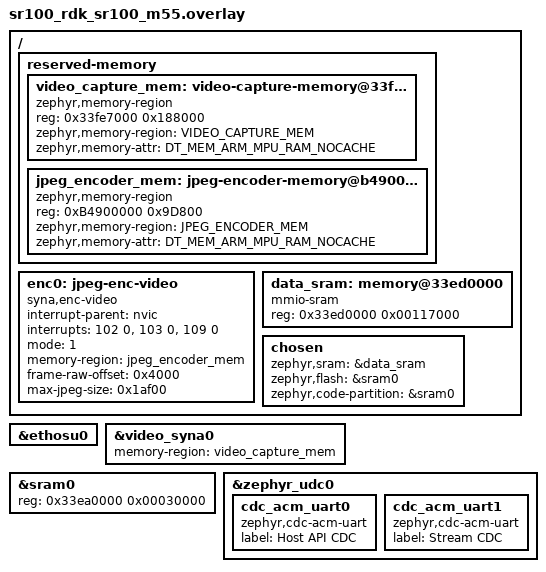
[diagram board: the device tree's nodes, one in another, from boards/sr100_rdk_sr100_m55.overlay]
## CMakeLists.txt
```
cmake_minimum_required(VERSION 3.20.0)
find_package(Zephyr REQUIRED HINTS $ENV{ZEPHYR_BASE})
project(person_detection_mipi)

set(NO_THREADSAFE_STATICS $<TARGET_PROPERTY:compiler-cpp,no_threadsafe_statics>)
zephyr_compile_options($<$<COMPILE_LANGUAGE:CXX>:${NO_THREADSAFE_STATICS}>)

target_sources(app PRIVATE
  src/main.c
  src/person_detection_mipi_capture.c
  src/person_detection_mipi_app.c
  src/person_detection_mipi_metadata.c
  src/person_detection_mipi_stream.c
  src/person_detection_mipi_inference.cpp
  src/person_detection_mipi_cmsis_shim.c
  src/infer_utils.c
  src/stream_cdc_transport.c
)
```

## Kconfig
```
# Copyright (c) 2026 Synaptics Incorporated
# SPDX-License-Identifier: Apache-2.0

mainmenu "Person Detection MIPI Sample"

config PERSON_DETECTION_MIPI_USECASE_ID
	int "UC manager usecase ID"
	default 2

config PERSON_DETECTION_MIPI_HOST_API_READY_TIMEOUT_MS
	int "Host API ready timeout (ms)"
	default 5000

config PERSON_DETECTION_MODEL_FLASH_ADDR
	hex "XIP flash address of the model binary"
	default 0x3C629000
	help
	  Start address in the XIP flash region where the TFLite model binary
	  has been programmed. Board-specific; adjust to match the flash
	  partition layout of the target hardware.

config PERSON_DETECTION_INPUT_FLASH_ADDR
	hex "XIP flash address of the input image binary"
	default 0x3CA00000
	help
	  Start address in the XIP flash region where the raw input image
	  binary has been programmed.

config PERSON_DETECTION_MODEL_SIZE
	int "Size of the model binary in bytes"
	default 1160832
	help
	  Byte length of the model binary stored at
	  PERSON_DETECTION_MODEL_FLASH_ADDR. Must match the actual file size
	  of the programmed model; a mismatch will silently copy wrong data.

source "Kconfig.zephyr"
```

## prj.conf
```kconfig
CONFIG_CPP=y
CONFIG_STD_CPP17=y
CONFIG_CONSOLE=y
CONFIG_PRINTK=y
CONFIG_STDOUT_CONSOLE=y
CONFIG_TENSORFLOW_LITE_MICRO=y
CONFIG_MAIN_STACK_SIZE=65536
CONFIG_SIZE_OPTIMIZATIONS=y
CONFIG_FPU=y
# Ethos-U55 NPU
CONFIG_ETHOS_U=y
CONFIG_ETHOS_U55_128=y
CONFIG_HEAP_MEM_POOL_SIZE=16384
CONFIG_LOG=n

CONFIG_VIDEO=y
CONFIG_VIDEO_INIT_PRIORITY=90
CONFIG_VIDEO_SYNA_MIPI=y
CONFIG_VIDEO_SYNA_ENC=y
CONFIG_VIDEO_SYNA_MIPI_INIT_PRIORITY=110
CONFIG_VIDEO_BUFFER_POOL_HEAP_SIZE=320000
CONFIG_VIDEO_BUFFER_POOL_NUM_MAX=4
CONFIG_VIDEO_BUFFER_POOL_ALIGN=64
CONFIG_POLL=y

CONFIG_GPIO=y
CONFIG_SERIAL=y
CONFIG_UART_INTERRUPT_DRIVEN=y
CONFIG_UART_LINE_CTRL=y
CONFIG_REBOOT=y

CONFIG_USB_DEVICE_STACK_NEXT=y
CONFIG_CDC_ACM_SERIAL_INITIALIZE_AT_BOOT=n
CONFIG_USBD_CDC_ACM_CLASS=y
CONFIG_USBD_MAX_SPEED_FULL=y
CONFIG_UDC_DRIVER_HIGH_SPEED_SUPPORT_ENABLED=n
CONFIG_USBD_BOS_SUPPORT=n
CONFIG_USBD_VREQ_SUPPORT=n
CONFIG_UDC_BUF_POOL_SIZE=2048
CONFIG_USBD_MAX_UDC_MSG=8
CONFIG_USBD_MSG_SLAB_COUNT=8
CONFIG_USBD_HWINFO_DEVID_LENGTH=8
CONFIG_USBD_THREAD_STACK_SIZE=2048
CONFIG_UDC_DWC2_STACK_SIZE=2048
CONFIG_USBD_LOG_LEVEL_ERR=y
CONFIG_UDC_DRIVER_LOG_LEVEL_ERR=y
CONFIG_USBD_CDC_ACM_LOG_LEVEL_ERR=y

CONFIG_SERVICE_HOST_API_ENABLED=y
CONFIG_SERVICE_USB_HOST_API_ENABLED=y
CONFIG_SERVICE_SYSTEM_ENABLED=y
CONFIG_SERVICE_UC_MANAGER_ENABLED=y
CONFIG_ACTIVE_INTERFACE_USB=y
CONFIG_HOST_API_AUTO_START=y
CONFIG_HOST_API_USB_VID=0xCAFE
CONFIG_HOST_API_USB_PID=0x4002
CONFIG_HOST_API_THREAD_STACK_SIZE=4096
CONFIG_HOST_API_TASK_PRIORITY=5
CONFIG_HOST_API_SDK_VER_MAJOR=0
CONFIG_HOST_API_SDK_VER_MINOR=9
CONFIG_HOST_API_SDK_VER_REVISION=7
```

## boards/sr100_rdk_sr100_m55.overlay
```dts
/*
 * Keep the Ethos-U activations in system RAM and reserve a non-cached
 * buffer pool for live MIPI capture.
 *
 * The board's default code partition is ITCM, which is too small for this
 * sample once TFLM, host API and live MIPI support are enabled. Move the
 * executable image to SRAM and keep runtime data in a separate SRAM window.
 */

#include <zephyr/dt-bindings/memory-attr/memory-attr-arm.h>

/ {
	reserved-memory {
		#address-cells = <1>;
		#size-cells = <1>;
		ranges;

		video_capture_mem: video-capture-memory@33fe7000 {
			compatible = "zephyr,memory-region", "mmio-sram";
			reg = <0x33fe7000 0x188000>;
			zephyr,memory-region = "VIDEO_CAPTURE_MEM";
			zephyr,memory-attr = <DT_MEM_ARM_MPU_RAM_NOCACHE>;
		};

		jpeg_encoder_mem: jpeg-encoder-memory@b4900000 {
			compatible = "zephyr,memory-region", "mmio-sram";
			reg = <0xB4900000 0x9D800>;
			zephyr,memory-region = "JPEG_ENCODER_MEM";
			zephyr,memory-attr = <DT_MEM_ARM_MPU_RAM_NOCACHE>;
		};
	};

	enc0: jpeg-enc-video {
		compatible = "syna,enc-video";
		status = "okay";
		interrupt-parent = <&nvic>;
		interrupts = <102 0>, <103 0>, <109 0>;
		interrupt-names = "frame-done", "fmin1-stored", "status";
		mode = <1>;
		memory-region = <&jpeg_encoder_mem>;
		frame-raw-offset = <0x4000>;
		max-jpeg-size = <0x1af00>;
	};
};

&ethosu0 {
	/delete-property/ fast-memory-region;
};

&video_syna0 {
	memory-region = <&video_capture_mem>;
};

&sram0 {
	/*
	 * Put code/rodata here so the application no longer depends on the
	 * 128 KB ITCM code partition. The current image uses about 149 KB of
	 * ROM, so 192 KB leaves margin while preserving the rest of SRAM for
	 * data sections.
	 */
	reg = <0x33ea0000 0x00030000>;
	ranges = <0x0 0x33ea0000 0x00030000>;
};

/ {
	data_sram: memory@33ed0000 {
		compatible = "mmio-sram";
		reg = <0x33ed0000 0x00117000>;
		#address-cells = <1>;
		#size-cells = <1>;
		ranges = <0x0 0x33ed0000 0x00117000>;
	};

	chosen {
		zephyr,sram = &data_sram;
		zephyr,flash = &sram0;
		zephyr,code-partition = &sram0;
	};
};

&zephyr_udc0 {
	cdc_acm_uart0: cdc_acm_uart0 {
		compatible = "zephyr,cdc-acm-uart";
		label = "Host API CDC";
	};

	cdc_acm_uart1: cdc_acm_uart1 {
		compatible = "zephyr,cdc-acm-uart";
		label = "Stream CDC";
	};
};
```

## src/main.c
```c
/*
 * Copyright (c) 2026 Synaptics Incorporated
 *
 * SPDX-License-Identifier: Apache-2.0
 */

/**
 * @file
 * @brief Host API controlled person detection MIPI sample shell
 */

#include <errno.h>
#include <stdint.h>

#include <zephyr/kernel.h>
#include <zephyr/sys/printk.h>

#include "person_detection_mipi_app.h"
#include "service_uc_manager_interface.h"

bool host_api_is_ready(void);

void host_api_loaded_apps_report(void)
{
	printk("zephyr_person_detection_mipi\n");
}

static int register_person_detection_usecase(void)
{
	static const uc_operations_t ops = {
		.create = person_detection_mipi_app_create,
		.start = person_detection_mipi_app_start,
		.stop = person_detection_mipi_app_stop,
		.resume = person_detection_mipi_app_resume,
		.kill = person_detection_mipi_app_kill,
	};

	return uc_manager_register_usecase((uint8_t)CONFIG_PERSON_DETECTION_MIPI_USECASE_ID,
					   &ops);
}

int main(void)
{
	int ret;

	printk("person_detection_mipi: main start\n");

	ret = register_person_detection_usecase();
	if (ret != 0) {
		printk("person_detection_mipi: usecase register failed: %d\n", ret);
		return ret;
	}

	printk("person_detection_mipi: usecase registered, waiting for host api\n");

	for (int elapsed = 0; elapsed < CONFIG_PERSON_DETECTION_MIPI_HOST_API_READY_TIMEOUT_MS;
	     elapsed += 10) {
		if (host_api_is_ready()) {
			printk("person_detection_mipi: host api ready\n");
			while (true) {
				k_sleep(K_FOREVER);
			}
		}

		k_msleep(10);
	}

	printk("person_detection_mipi: host api ready timeout\n");
	return -ETIMEDOUT;
}
```

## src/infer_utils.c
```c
/*
 * Copyright (c) 2026 Synaptics Incorporated
 *
 * SPDX-License-Identifier: Apache-2.0
 */

/**
 * @file
 * @brief Person-detection inference utilities: preprocess and postprocess implementation
 */

#include "infer_utils.h"
#include <stdint.h>
#include <math.h>

#ifdef __ARM_FEATURE_MVE
#include <arm_mve.h>
#endif

int infer_preprocess(void *addr, int width, int height)
{
    if (!addr || width <= 0 || height <= 0)
        return -1;

    size_t   total = (size_t)width * (size_t)height * 3u;
    uint8_t *p     = (uint8_t *)addr;

#ifdef __ARM_FEATURE_MVE
    const uint8x16_t mask = vdupq_n_u8(0x80u);
    int32_t          n    = (int32_t)total;
    do {
        mve_pred16_t pred = vctp8q((uint32_t)n);
        uint8x16_t   v    = vldrbq_z_u8(p, pred);
        vstrbq_p_u8(p, veorq_u8(v, mask), pred);
        p += 16;
        n -= 16;
    } while (n > 0);
#else
    if (((uintptr_t)addr & 3u) == 0u) {
        uint32_t      *p32  = (uint32_t *)addr;
        size_t         n32  = total >> 2;
        size_t         tail = total & 3u;
        const uint32_t M    = 0x80808080u;
        size_t i = 0;

        for (; i + 3 < n32; i += 4) {
            p32[i    ] ^= M;
            p32[i + 1] ^= M;
            p32[i + 2] ^= M;
            p32[i + 3] ^= M;
        }
        for (; i < n32; ++i) {
            p32[i] ^= M;
        }
        p = (uint8_t *)addr + (n32 << 2);
        for (size_t j = 0; j < tail; ++j) {
            p[j] ^= 0x80u;
        }
    } else {
        for (size_t i = 0; i < total; ++i) {
            p[i] ^= 0x80u;
        }
    }
#endif

    return 0;
}

/* Postprocessing constants */
static const float k_scale_x2y2   = 2.2298152446746826f;
static const int   k_zp_x2y2      = -84;
static const float k_scale_x1y1   = 2.4782917499542236f;
static const int   k_zp_x1y1      = -128;
static const float k_scale_scores = 0.00390625f; /* 1/256 */
static const int   k_zp_scores    = -128;

static float iou_xywh(const float *a, const float *b)
{
    float ax1 = a[0], ay1 = a[1], ax2 = a[0]+a[2], ay2 = a[1]+a[3];
    float bx1 = b[0], by1 = b[1], bx2 = b[0]+b[2], by2 = b[1]+b[3];
    float inter_w  = fmaxf(0.f, fminf(ax2,bx2) - fmaxf(ax1,bx1));
    float inter_h  = fmaxf(0.f, fminf(ay2,by2) - fmaxf(ay1,by1));
    float inter    = inter_w * inter_h;
    float uni      = a[2]*a[3] + b[2]*b[3] - inter;
    return (uni <= 0.f) ? 0.f : inter / uni;
}

static void min_heap_swap(int *h, int a, int b)
{
    int t = h[a]; h[a] = h[b]; h[b] = t;
}

static void min_heap_sift_up(int *h, int cnt, const float *scores, int cur)
{
    while (cur > 0 && cur < cnt) {
        int parent = (cur - 1) >> 1;
        if (scores[h[cur]] < scores[h[parent]]) {
            min_heap_swap(h, cur, parent);
            cur = parent;
        } else {
            break;
        }
    }
}

static void min_heap_sift_down(int *h, int cnt, const float *scores, int cur)
{
    for (;;) {
        int left = (cur << 1) + 1;
        int right = left + 1;
        int smallest = cur;
        if (left < cnt && scores[h[left]] < scores[h[smallest]]) smallest = left;
        if (right < cnt && scores[h[right]] < scores[h[smallest]]) smallest = right;
        if (smallest != cur) {
            min_heap_swap(h, cur, smallest);
            cur = smallest;
        } else break;
    }
}

int infer_postprocess(const void *box1_addr, size_t box1_size,
                      const void *cls_addr,  size_t cls_size,
                      const void *box2_addr, size_t box2_size,
                      int max_out, detection_t *out_dets, int *out_count)
{
    if (!box1_addr || !cls_addr || !box2_addr || !out_dets || !out_count)
        return -1;

    const int N = MAX_BOXES;
    if (box1_size < (size_t)N*2 || box2_size < (size_t)N*2 || cls_size < (size_t)N)
        return -2;

    const int8_t *box1 = (const int8_t *)box1_addr;
    const int8_t *box2 = (const int8_t *)box2_addr;
    const int8_t *cls  = (const int8_t *)cls_addr;

    /* Static temporaries to avoid heap usage */
    static float x1[MAX_BOXES];
    static float y1[MAX_BOXES];
    static float x2[MAX_BOXES];
    static float y2[MAX_BOXES];
    static float scores[MAX_BOXES];
    static float boxes[MAX_BOXES * 4u];
    static uint8_t valid[MAX_BOXES];

    /* Scalar decode (portable) */
    for (int i = 0; i < N; ++i) {
        x2[i]     = (float)((int)box1[i*2+0] - k_zp_x2y2)  * k_scale_x2y2;
        y2[i]     = (float)((int)box1[i*2+1] - k_zp_x2y2)  * k_scale_x2y2;
        x1[i]     = (float)((int)box2[i*2+0] - k_zp_x1y1)  * k_scale_x1y1;
        y1[i]     = (float)((int)box2[i*2+1] - k_zp_x1y1)  * k_scale_x1y1;
        scores[i] = (float)((int)cls[i]       - k_zp_scores) * k_scale_scores;
    }

    for (int i = 0; i < N; ++i) {
        float xmin = fminf(x1[i], x2[i]);
        float xmax = fmaxf(x1[i], x2[i]);
        float ymin = fminf(y1[i], y2[i]);
        float ymax = fmaxf(y1[i], y2[i]);
        float bw   = xmax - xmin;
        float bh   = ymax - ymin;
        if (bw > 1.f && bh > 1.f) {
            boxes[4*i+0] = xmin;
            boxes[4*i+1] = ymin;
            boxes[4*i+2] = bw;
            boxes[4*i+3] = bh;
            valid[i] = 1u;
        } else {
            valid[i] = 0u;
        }
    }

    const float conf_thresh = 0.25f;
    const float iou_thresh  = 0.6f;

    const int nms_cap = (max_out < NMS_MAX_KEEP) ? max_out : NMS_MAX_KEEP;
    if (nms_cap <= 0) {
        *out_count = 0;
        return 0;
    }

    /* Bounded min-heap (by score) of candidate indices */
    int heap_cnt = 0;
    int heap_idx[NMS_MAX_KEEP];

    /* heap operations use static helpers defined above */

    for (int i = 0; i < N; ++i) {
        if (!valid[i]) continue;
        float s = scores[i];
        if (s <= conf_thresh) continue;
        if (heap_cnt < nms_cap) {
            heap_idx[heap_cnt] = i;
            min_heap_sift_up(heap_idx, heap_cnt + 1, scores, heap_cnt);
            heap_cnt++;
        } else if (s > scores[heap_idx[0]]) {
            heap_idx[0] = i;
            min_heap_sift_down(heap_idx, heap_cnt, scores, 0);
        }
    }

    if (heap_cnt == 0) {
        *out_count = 0;
        return 0;
    }

    /* Extract heap into candidates array in descending order */
    int candidates_count = heap_cnt;
    int candidates_arr[NMS_MAX_KEEP];
    for (int i = heap_cnt - 1; i >= 0; --i) {
        candidates_arr[i] = heap_idx[0];
        heap_idx[0] = heap_idx[heap_cnt - 1];
        heap_cnt--;
        if (heap_cnt > 0) min_heap_sift_down(heap_idx, heap_cnt, scores, 0);
    }

    /* Perform NMS on the top candidates */
    int num_kept = 0;
    int kept[NMS_MAX_KEEP];
    for (int i = 0; i < candidates_count && num_kept < nms_cap; ++i) {
        int idx = candidates_arr[i];
        float bi[4] = { boxes[4*idx], boxes[4*idx+1], boxes[4*idx+2], boxes[4*idx+3] };
        int suppress = 0;
        for (int j = 0; j < num_kept && !suppress; ++j) {
            int ki = kept[j];
            float bj[4] = { boxes[4*ki], boxes[4*ki+1], boxes[4*ki+2], boxes[4*ki+3] };
            if (iou_xywh(bi, bj) > iou_thresh)
                suppress = 1;
        }
        if (!suppress)
            kept[num_kept++] = idx;
    }

    /* Fill output detections */
    for (int i = 0; i < num_kept; ++i) {
        int idx = kept[i];
        out_dets[i].class_id = 0;
        out_dets[i].score    = scores[idx];
        out_dets[i].x        = boxes[4*idx+0];
        out_dets[i].y        = boxes[4*idx+1];
        out_dets[i].w        = boxes[4*idx+2];
        out_dets[i].h        = boxes[4*idx+3];
    }

    *out_count = num_kept;
    return 0;
}
```

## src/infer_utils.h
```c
/*
 * Copyright (c) 2026 Synaptics Incorporated
 *
 * SPDX-License-Identifier: Apache-2.0
 */

/**
 * @file
 * @brief Person-detection inference utilities: preprocess and postprocess API
 */

#ifndef INFER_UTILS_H_
#define INFER_UTILS_H_

#include <stddef.h>

/**
 * @brief Maximum number of detections the postprocessor will return
 */
#define MAX_DETECTIONS   16

/**
 * @brief Maximum number of candidate boxes produced by the network
 */
#define MAX_BOXES        600

/**
 * @brief Maximum number of boxes to keep during non-max suppression
 */
#define NMS_MAX_KEEP     6

/**
 * @struct detection_t
 * @brief Single detection result in pixel coordinates
 *
 * - `class_id` currently always 0 for the person model
 * - `score` is the confidence (0.0 - 1.0)
 * - `x, y` are the top-left pixel coordinates
 * - `w, h` are the width and height in pixels
 */
typedef struct {
    int   class_id;
    float score;
    float x;
    float y;
    float w;
    float h;
} detection_t;

#ifdef __cplusplus
extern "C" {
#endif

/**
 * @brief Preprocess an input image in-place for the model.
 *
 * The sample stores inputs in flash as interleaved RGB uint8. The model
 * expects int8 with a zero-point conversion performed by XOR 0x80. This
 * function applies that conversion in-place.
 *
 * @param addr Pointer to image buffer (must be writable). The buffer layout
 *             is interleaved RGB, row-major, size = width * height * 3 bytes.
 * @param width Image width in pixels.
 * @param height Image height in pixels.
 * @return 0 on success, negative on error (invalid args).
 */
int infer_preprocess(void *addr, int width, int height);

/**
 * @brief Postprocess raw network outputs into detection_t array.
 *
 * The function decodes the model's three output tensors into bounding boxes
 * and scores, applies non-max suppression, and fills the provided output
 * array with up to `max_out` detections.
 *
 * @param box1_addr Pointer to first box tensor data (raw int8/uint8 as produced by the model)
 * @param box1_size Size in bytes of the first box tensor.
 * @param cls_addr  Pointer to class/score tensor data.
 * @param cls_size  Size in bytes of the class/score tensor.
 * @param box2_addr Pointer to second box tensor data (if applicable).
 * @param box2_size Size in bytes of the second box tensor.
 * @param max_out Maximum number of detections to write into `out_dets`.
 * @param out_dets Pointer to caller-allocated array of `detection_t` of length >= max_out.
 * @param out_count Pointer to int updated with the number of detections written.
 * @return 0 on success, negative on error.
 */
int infer_postprocess(const void *box1_addr, size_t box1_size,
                      const void *cls_addr,  size_t cls_size,
                      const void *box2_addr, size_t box2_size,
                      int max_out, detection_t *out_dets, int *out_count);

#ifdef __cplusplus
}
#endif

#endif /* INFER_UTILS_H_ */
```

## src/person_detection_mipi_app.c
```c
/*
 * Copyright (c) 2026 Synaptics Incorporated
 *
 * SPDX-License-Identifier: Apache-2.0
 */

#include "person_detection_mipi_app.h"

#include <errno.h>
#include <stdbool.h>

#include "person_detection_mipi_capture.h"
#include "person_detection_mipi_inference.h"
#include "person_detection_mipi_metadata.h"
#include "person_detection_mipi_stream.h"

#include <zephyr/kernel.h>
#include <zephyr/sys/printk.h>

enum person_detection_mipi_state {
	APP_STATE_UNINITIALIZED = 0,
	APP_STATE_CREATED,
	APP_STATE_RUNNING,
	APP_STATE_STOPPED,
};

struct person_detection_mipi_context {
	struct k_mutex lock;
	struct k_sem inference_ready_sem;
	struct k_sem inference_stopped_sem;
	struct k_thread inference_thread;
	enum person_detection_mipi_state state;
	bool stop_requested;
	bool inference_running;
	bool initialized;
};

static struct person_detection_mipi_context app_ctx;

K_THREAD_STACK_DEFINE(person_detection_mipi_inference_stack, 4096);

static void app_context_init(struct person_detection_mipi_context *ctx)
{
	if (ctx->initialized) {
		return;
	}

	k_mutex_init(&ctx->lock);
	k_sem_init(&ctx->inference_ready_sem, 0, 1);
	k_sem_init(&ctx->inference_stopped_sem, 0, 1);
	ctx->state = APP_STATE_UNINITIALIZED;
	ctx->initialized = true;
}

static void person_detection_mipi_inference_worker(void *arg1, void *arg2, void *arg3)
{
	struct person_detection_mipi_context *ctx = arg1;
	struct person_detection_mipi_capture_frame frame;
	struct person_detection_mipi_inference_result result;
	uint8_t *scratch_frame = person_detection_mipi_capture_scratch_frame_buffer();
	uint32_t last_sequence = 0U;
	uint32_t loops_without_frame = 0U;
	uint32_t loops_without_new_frame = 0U;
	uint32_t inference_count = 0U;
	bool ready_signaled = false;

	ARG_UNUSED(arg2);
	ARG_UNUSED(arg3);

	printk("person_detection_mipi: inference worker: started\n");

	while (true) {
		bool stop_requested;
		int ret;

		k_mutex_lock(&ctx->lock, K_FOREVER);
		stop_requested = ctx->stop_requested;
		k_mutex_unlock(&ctx->lock);

		if (stop_requested) {
			break;
		}

		ret = person_detection_mipi_capture_get_latest(&frame, scratch_frame,
							       PERSON_DETECTION_MIPI_MODEL_RAW_FRAME_SIZE);
		if (ret != 0) {
			loops_without_frame++;
			if ((loops_without_frame == 1U) || ((loops_without_frame % 100U) == 0U)) {
				printk("person_detection_mipi: inference worker: no frame yet (ret=%d loops=%u)\n",
				       ret, loops_without_frame);
			}
			k_msleep(10);
			continue;
		}
		loops_without_frame = 0U;

		if ((frame.sequence == 0U) || (frame.sequence == last_sequence) || !frame.valid) {
			loops_without_new_frame++;
			if ((loops_without_new_frame == 1U) ||
			    ((loops_without_new_frame % 100U) == 0U)) {
				printk("person_detection_mipi: inference worker: waiting for new frame (seq=%u last=%u valid=%d loops=%u)\n",
				       frame.sequence, last_sequence, frame.valid ? 1 : 0,
				       loops_without_new_frame);
			}
			k_msleep(10);
			continue;
		}
		loops_without_new_frame = 0U;

		printk("person_detection_mipi: inference worker: running frame seq=%u bytes=%u\n",
		       frame.sequence, frame.bytesused);

		ret = person_detection_mipi_inference_run_raw8_frame(frame.data, frame.bytesused,
								     &result);
		if (ret != 0) {
			printk("person_detection_mipi: inference worker: inference failed for seq=%u ret=%d\n",
			       frame.sequence, ret);
			continue;
		}

		inference_count++;
		printk("person_detection_mipi: inference worker: frame seq=%u done invoke=%ums detections=%d total=%u\n",
		       frame.sequence, result.invoke_time_ms, result.detection_count, inference_count);
		if (result.detection_count > 0) {
			for (int i = 0; i < result.detection_count; i++) {
				const detection_t *det = &result.detections[i];
				float x1 = det->x;
				float y1 = det->y;
				float x2 = det->x + det->w;
				float y2 = det->y + det->h;

				printk("UC Person detection - [Frame %u] Detection number %d: Class [%d], Box [%0.3f, %0.3f, %0.3f, %0.3f], Score [%0.3f]\n",
				       frame.sequence, i + 1, det->class_id,
				       (double)x1, (double)y1, (double)x2, (double)y2,
				       (double)det->score);
			}
		}

		ret = person_detection_mipi_metadata_update(frame.sequence,
							   CONFIG_PERSON_DETECTION_MIPI_USECASE_ID,
							   &result);
		if (ret != 0) {
			printk("person_detection_mipi: inference worker: metadata update failed for seq=%u ret=%d\n",
			       frame.sequence, ret);
			continue;
		}
		printk("person_detection_mipi: inference worker: metadata updated for seq=%u\n",
		       frame.sequence);

		last_sequence = frame.sequence;

		if (!ready_signaled) {
			ready_signaled = true;
			k_sem_give(&ctx->inference_ready_sem);
		}
	}

	k_mutex_lock(&ctx->lock, K_FOREVER);
	ctx->inference_running = false;
	k_mutex_unlock(&ctx->lock);

	printk("person_detection_mipi: inference worker: stopped after %u successful inference(s)\n",
	       inference_count);

	if (!ready_signaled) {
		k_sem_give(&ctx->inference_ready_sem);
	}

	k_sem_give(&ctx->inference_stopped_sem);
}

int person_detection_mipi_app_create(void)
{
	struct person_detection_mipi_context *ctx = &app_ctx;
	int ret;

	app_context_init(ctx);
	k_mutex_lock(&ctx->lock, K_FOREVER);

	if (ctx->state != APP_STATE_UNINITIALIZED) {
		k_mutex_unlock(&ctx->lock);
		return 0;
	}

	printk("person_detection_mipi: create: initializing inference\n");
	ret = person_detection_mipi_inference_init();
	if (ret != 0) {
		printk("person_detection_mipi: create: inference init failed: %d\n", ret);
		k_mutex_unlock(&ctx->lock);
		return ret;
	}

	printk("person_detection_mipi: create: initializing MIPI capture\n");
	ret = person_detection_mipi_capture_init();
	if (ret != 0) {
		printk("person_detection_mipi: create: MIPI capture init failed: %d\n", ret);
		k_mutex_unlock(&ctx->lock);
		return ret;
	}

	printk("person_detection_mipi: create: initializing JPEG stream\n");
	ret = person_detection_mipi_stream_init();
	if (ret != 0) {
		printk("person_detection_mipi: create: JPEG stream disabled: %d\n", ret);
	}

	person_detection_mipi_metadata_reset();

	ctx->state = APP_STATE_CREATED;

	k_mutex_unlock(&ctx->lock);
	printk("person_detection_mipi: create: complete\n");
	return 0;
}

int person_detection_mipi_app_start(void)
{
	struct person_detection_mipi_context *ctx = &app_ctx;
	int ret = 0;

	app_context_init(ctx);
	k_mutex_lock(&ctx->lock, K_FOREVER);

	if (ctx->state == APP_STATE_RUNNING) {
		k_mutex_unlock(&ctx->lock);
		return 0;
	}

	if (ctx->state == APP_STATE_STOPPED) {
		k_mutex_unlock(&ctx->lock);
		return person_detection_mipi_app_resume();
	}

	if (ctx->state != APP_STATE_CREATED) {
		k_mutex_unlock(&ctx->lock);
		return -EPERM;
	}

	k_mutex_unlock(&ctx->lock);

	ret = person_detection_mipi_stream_start();
	if (ret != 0) {
		printk("person_detection_mipi: start: JPEG stream disabled: %d\n", ret);
	}

	printk("person_detection_mipi: start: starting MIPI capture\n");
	ret = person_detection_mipi_capture_start();
	if (ret != 0) {
		(void)person_detection_mipi_stream_stop();
		printk("person_detection_mipi: start: MIPI capture failed: %d\n", ret);
		return ret;
	}

	person_detection_mipi_metadata_reset();

	k_mutex_lock(&ctx->lock, K_FOREVER);
	ctx->stop_requested = false;
	ctx->inference_running = true;
	k_sem_reset(&ctx->inference_ready_sem);
	k_sem_reset(&ctx->inference_stopped_sem);
	k_mutex_unlock(&ctx->lock);

	k_thread_create(&ctx->inference_thread, person_detection_mipi_inference_stack,
			K_THREAD_STACK_SIZEOF(person_detection_mipi_inference_stack),
			person_detection_mipi_inference_worker, ctx, NULL, NULL,
			CONFIG_HOST_API_TASK_PRIORITY, 0, K_NO_WAIT);
	k_thread_name_set(&ctx->inference_thread, "pd_mipi_infer");

	printk("person_detection_mipi: start: waiting for first inference\n");
	ret = k_sem_take(&ctx->inference_ready_sem, K_SECONDS(5));
	if (ret != 0) {
		printk("person_detection_mipi: start: first inference timeout: %d\n", ret);
		k_mutex_lock(&ctx->lock, K_FOREVER);
		ctx->stop_requested = true;
		k_mutex_unlock(&ctx->lock);
		(void)person_detection_mipi_stream_stop();
		(void)person_detection_mipi_capture_stop();
		(void)k_sem_take(&ctx->inference_stopped_sem, K_SECONDS(5));
		return ret;
	}

	k_mutex_lock(&ctx->lock, K_FOREVER);
	ctx->state = APP_STATE_RUNNING;
	k_mutex_unlock(&ctx->lock);
	printk("person_detection_mipi: start: complete\n");
	return 0;
}

int person_detection_mipi_app_stop(void)
{
	struct person_detection_mipi_context *ctx = &app_ctx;
	int ret = 0;

	app_context_init(ctx);
	k_mutex_lock(&ctx->lock, K_FOREVER);

	if (ctx->state == APP_STATE_STOPPED) {
		k_mutex_unlock(&ctx->lock);
		return 0;
	}

	if (ctx->state != APP_STATE_RUNNING) {
		k_mutex_unlock(&ctx->lock);
		return -EPERM;
	}

	ctx->stop_requested = true;
	k_mutex_unlock(&ctx->lock);

	ret = person_detection_mipi_stream_pause();
	if (ret != 0) {
		printk("person_detection_mipi: stop: JPEG stream pause failed: %d\n", ret);
		return ret;
	}

	ret = k_sem_take(&ctx->inference_stopped_sem, K_SECONDS(5));
	if (ret != 0) {
		return ret;
	}

	k_mutex_lock(&ctx->lock, K_FOREVER);
	ctx->state = APP_STATE_STOPPED;
	k_mutex_unlock(&ctx->lock);
	printk("person_detection_mipi: stop: complete\n");
	return 0;
}

int person_detection_mipi_app_resume(void)
{
	struct person_detection_mipi_context *ctx = &app_ctx;
	int ret;

	app_context_init(ctx);
	k_mutex_lock(&ctx->lock, K_FOREVER);
	if (ctx->state != APP_STATE_STOPPED) {
		k_mutex_unlock(&ctx->lock);
		return -EPERM;
	}
	k_mutex_unlock(&ctx->lock);

	printk("person_detection_mipi: resume: resuming paused usecase\n");

	ret = person_detection_mipi_stream_resume();
	if (ret != 0) {
		printk("person_detection_mipi: resume: JPEG stream resume failed: %d\n", ret);
		return ret;
	}

	k_mutex_lock(&ctx->lock, K_FOREVER);
	ctx->stop_requested = false;
	ctx->inference_running = true;
	k_sem_reset(&ctx->inference_ready_sem);
	k_sem_reset(&ctx->inference_stopped_sem);
	k_mutex_unlock(&ctx->lock);

	k_thread_create(&ctx->inference_thread, person_detection_mipi_inference_stack,
			K_THREAD_STACK_SIZEOF(person_detection_mipi_inference_stack),
			person_detection_mipi_inference_worker, ctx, NULL, NULL,
			CONFIG_HOST_API_TASK_PRIORITY, 0, K_NO_WAIT);
	k_thread_name_set(&ctx->inference_thread, "pd_mipi_infer");

	printk("person_detection_mipi: resume: waiting for first inference\n");
	ret = k_sem_take(&ctx->inference_ready_sem, K_SECONDS(5));
	if (ret != 0) {
		printk("person_detection_mipi: resume: first inference timeout: %d\n", ret);
		k_mutex_lock(&ctx->lock, K_FOREVER);
		ctx->stop_requested = true;
		k_mutex_unlock(&ctx->lock);
		(void)person_detection_mipi_stream_pause();
		(void)k_sem_take(&ctx->inference_stopped_sem, K_SECONDS(5));
		return ret;
	}

	k_mutex_lock(&ctx->lock, K_FOREVER);
	ctx->state = APP_STATE_RUNNING;
	k_mutex_unlock(&ctx->lock);

	printk("person_detection_mipi: resume: complete\n");
	return 0;
}

int person_detection_mipi_app_kill(void)
{
	struct person_detection_mipi_context *ctx = &app_ctx;
	enum person_detection_mipi_state state;
	int ret;

	app_context_init(ctx);
	k_mutex_lock(&ctx->lock, K_FOREVER);
	state = ctx->state;
	k_mutex_unlock(&ctx->lock);

	if (state == APP_STATE_RUNNING) {
		ret = person_detection_mipi_app_stop();
		if (ret != 0) {
			printk("person_detection_mipi: kill: stop failed: %d\n", ret);
			return ret;
		}
		state = APP_STATE_STOPPED;
	}

	if (state == APP_STATE_STOPPED) {
		ret = person_detection_mipi_stream_stop();
		if (ret != 0) {
			printk("person_detection_mipi: kill: stream stop failed: %d\n", ret);
			return ret;
		}

		ret = person_detection_mipi_capture_stop();
		if (ret != 0) {
			printk("person_detection_mipi: kill: capture stop failed: %d\n", ret);
			return ret;
		}
	}

	person_detection_mipi_metadata_reset();

	k_mutex_lock(&ctx->lock, K_FOREVER);
	ctx->stop_requested = false;
	ctx->inference_running = false;
	ctx->state = APP_STATE_UNINITIALIZED;
	k_mutex_unlock(&ctx->lock);

	printk("person_detection_mipi: kill: complete\n");
	return 0;
}

int person_detection_mipi_app_get_latest_metadata(char *dst, size_t dst_size)
{
	return person_detection_mipi_metadata_get(dst, dst_size);
}

int person_detection_mipi_app_get_latest_snapshot(
	struct person_detection_mipi_metadata_snapshot *snapshot)
{
	return person_detection_mipi_metadata_snapshot_get(snapshot);
}

bool person_detection_mipi_app_is_running(void)
{
	struct person_detection_mipi_context *ctx = &app_ctx;
	bool running;

	app_context_init(ctx);
	k_mutex_lock(&ctx->lock, K_FOREVER);
	running = (ctx->state == APP_STATE_RUNNING);
	k_mutex_unlock(&ctx->lock);

	return running;
}
```

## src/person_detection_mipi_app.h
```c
/*
 * Copyright (c) 2026 Synaptics Incorporated
 *
 * SPDX-License-Identifier: Apache-2.0
 */

#ifndef PERSON_DETECTION_MIPI_APP_H_
#define PERSON_DETECTION_MIPI_APP_H_

#include <stddef.h>
#include <stdbool.h>

#include "person_detection_mipi_metadata.h"

#ifdef __cplusplus
extern "C" {
#endif

int person_detection_mipi_app_create(void);
int person_detection_mipi_app_start(void);
int person_detection_mipi_app_stop(void);
int person_detection_mipi_app_resume(void);
int person_detection_mipi_app_kill(void);
int person_detection_mipi_app_get_latest_metadata(char *dst, size_t dst_size);
int person_detection_mipi_app_get_latest_snapshot(
	struct person_detection_mipi_metadata_snapshot *snapshot);
bool person_detection_mipi_app_is_running(void);

#ifdef __cplusplus
}
#endif

#endif /* PERSON_DETECTION_MIPI_APP_H_ */
```

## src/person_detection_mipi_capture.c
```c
/*
 * Copyright (c) 2026 Synaptics Incorporated
 *
 * SPDX-License-Identifier: Apache-2.0
 */

#include "person_detection_mipi_capture.h"

#include <errno.h>
#include <string.h>

#include <zephyr/device.h>
#include <zephyr/devicetree.h>
#include <zephyr/drivers/video.h>
#include <zephyr/kernel.h>
#include <zephyr/sys/printk.h>
#include <zephyr/sys/util.h>

#include "person_detection_mipi_stream.h"

#define MIPI_DEV_NODE DT_NODELABEL(video_syna0)

#if !DT_NODE_EXISTS(MIPI_DEV_NODE)
#error "Devicetree node 'video_syna0' is required for this sample"
#endif

#if !DT_NODE_HAS_PROP(MIPI_DEV_NODE, memory_region)
#error "video_syna0 must provide a memory-region for live MIPI capture"
#endif

#define CAPTURE_MEM_NODE DT_PHANDLE(MIPI_DEV_NODE, memory_region)
#define CAPTURE_MEM_BASE DT_REG_ADDR(CAPTURE_MEM_NODE)
#define CAPTURE_MEM_SIZE DT_REG_SIZE(CAPTURE_MEM_NODE)

#define APP_CAPTURE_TIMEOUT K_SECONDS(5)
#define APP_CAPTURE_FIRST_FRAME_TIMEOUT K_SECONDS(5)
#define APP_CAPTURE_FRMIVAL_NUMERATOR 1U
#define APP_CAPTURE_FRMIVAL_DENOMINATOR 3U
#define APP_CAPTURE_BUFFER_COUNT 2U

/* The MIPI driver always DMA-writes one raw frame at the pool base. */
#define APP_CAPTURE_DMA_STAGING_OFFSET 0U
#define APP_CAPTURE_FULL_LATEST_FRAME_OFFSET \
	(APP_CAPTURE_DMA_STAGING_OFFSET + PERSON_DETECTION_MIPI_CAPTURE_FRAME_SIZE)
#define APP_CAPTURE_LATEST_FRAME_OFFSET \
	(APP_CAPTURE_FULL_LATEST_FRAME_OFFSET + PERSON_DETECTION_MIPI_CAPTURE_FRAME_SIZE)
#define APP_CAPTURE_SCRATCH_FRAME_OFFSET \
	(APP_CAPTURE_LATEST_FRAME_OFFSET + PERSON_DETECTION_MIPI_MODEL_RAW_FRAME_SIZE)
#define APP_CAPTURE_INPUT_BUF_OFFSET \
	(APP_CAPTURE_SCRATCH_FRAME_OFFSET + PERSON_DETECTION_MIPI_MODEL_RAW_FRAME_SIZE)
#define APP_CAPTURE_RESERVED_TOTAL_SIZE APP_CAPTURE_INPUT_BUF_OFFSET

BUILD_ASSERT(CAPTURE_MEM_SIZE >= APP_CAPTURE_RESERVED_TOTAL_SIZE,
	     "Capture reserved memory is too small for frame buffers");

static uint8_t *const app_capture_mem = (uint8_t *)CAPTURE_MEM_BASE;

enum capture_state {
	CAPTURE_STATE_UNINITIALIZED = 0,
	CAPTURE_STATE_READY,
	CAPTURE_STATE_RUNNING,
	CAPTURE_STATE_STOPPED,
};

struct capture_context {
	struct k_mutex lock;
	struct k_sem first_frame_sem;
	struct k_sem worker_stopped_sem;
	struct k_thread worker_thread;
	const struct device *mipi_dev;
	struct video_caps caps;
	struct video_format fmt;
	struct video_frmival frmival;
	struct video_buffer *vbufs[APP_CAPTURE_BUFFER_COUNT];
	enum capture_state state;
	bool initialized;
	bool stop_requested;
	bool stream_started;
	bool buffers_queued;
	bool latest_valid;
	int worker_result;
	uint32_t latest_bytesused;
	uint32_t latest_timestamp;
	uint32_t latest_sequence;
	uint32_t frames_captured;
};

static struct capture_context app_ctx;

K_THREAD_STACK_DEFINE(capture_worker_stack, 4096);

static void capture_context_init(struct capture_context *ctx)
{
	if (ctx->initialized) {
		return;
	}

	k_mutex_init(&ctx->lock);
	k_sem_init(&ctx->first_frame_sem, 0, 1);
	k_sem_init(&ctx->worker_stopped_sem, 0, 1);
	ctx->initialized = true;
}

static void drain_buffers(const struct device *dev)
{
	struct video_buffer *vbuf = NULL;
	uint32_t drained = 0U;

	while ((video_dequeue(dev, &vbuf, K_NO_WAIT) == 0) && (vbuf != NULL)) {
		drained++;
		vbuf->bytesused = 0U;
	}

	if (drained > 0U) {
		printk("person_detection_mipi: drained %u returned capture buffer(s)\n", drained);
	}
}

static int prepare_device_locked(struct capture_context *ctx)
{
	ctx->mipi_dev = DEVICE_DT_GET(MIPI_DEV_NODE);

	if (!device_is_ready(ctx->mipi_dev)) {
		return -ENODEV;
	}

	memset(&ctx->caps, 0, sizeof(ctx->caps));
	ctx->caps.type = VIDEO_BUF_TYPE_OUTPUT;

	return video_get_caps(ctx->mipi_dev, &ctx->caps);
}

static int configure_mipi_locked(struct capture_context *ctx)
{
	int ret;

	ctx->fmt = (struct video_format) {
		.type = VIDEO_BUF_TYPE_OUTPUT,
		.pixelformat = VIDEO_PIX_FMT_SRGGB8,
		.width = PERSON_DETECTION_MIPI_CAPTURE_WIDTH,
		.height = PERSON_DETECTION_MIPI_CAPTURE_HEIGHT,
		.pitch = PERSON_DETECTION_MIPI_CAPTURE_PITCH,
	};

	ret = video_set_format(ctx->mipi_dev, &ctx->fmt);
	if (ret != 0) {
		return ret;
	}

	printk("person_detection_mipi: negotiated fmt width=%u height=%u pitch=%u size=%u\n",
	       ctx->fmt.width, ctx->fmt.height, ctx->fmt.pitch, ctx->fmt.size);

	ctx->frmival = (struct video_frmival) {
		.numerator = APP_CAPTURE_FRMIVAL_NUMERATOR,
		.denominator = APP_CAPTURE_FRMIVAL_DENOMINATOR,
	};

	ret = video_set_frmival(ctx->mipi_dev, &ctx->frmival);
	if (ret != 0) {
		return ret;
	}

	return 0;
}

static int prepare_capture_buffers(struct capture_context *ctx)
{
	const size_t align = MAX(ctx->caps.buf_align, 1U);

	if (ctx->caps.min_vbuf_count > APP_CAPTURE_BUFFER_COUNT) {
		return -ENOMEM;
	}

	for (uint32_t i = 0U; i < APP_CAPTURE_BUFFER_COUNT; i++) {
		if (ctx->vbufs[i] == NULL) {
			ctx->vbufs[i] = video_buffer_aligned_alloc(ctx->fmt.size, align,
								   K_NO_WAIT);
			if (ctx->vbufs[i] == NULL) {
				printk("person_detection_mipi: capture buffer[%u] alloc failed\n",
				       i);
				return -ENOMEM;
			}
		}

		ctx->vbufs[i]->driver_data = NULL;
		ctx->vbufs[i]->type = VIDEO_BUF_TYPE_OUTPUT;
		ctx->vbufs[i]->bytesused = 0U;
		ctx->vbufs[i]->timestamp = 0U;
		printk("person_detection_mipi: capture buffer[%u] addr=%p size=%u\n", i,
		       ctx->vbufs[i]->buffer, ctx->vbufs[i]->size);
	}

	return 0;
}

static int queue_capture_buffers(struct capture_context *ctx)
{
	for (uint32_t i = 0U; i < APP_CAPTURE_BUFFER_COUNT; i++) {
		printk("person_detection_mipi: queue buffer[%u]\n", i);
		int ret = video_enqueue(ctx->mipi_dev, ctx->vbufs[i]);

		if (ret != 0) {
			printk("person_detection_mipi: queue buffer[%u] failed: %d\n", i, ret);
			return ret;
		}

		ctx->buffers_queued = true;
	}

	return 0;
}

static int copy_latest_frame_locked(struct capture_context *ctx, const struct video_buffer *src)
{
	if ((src == NULL) || (src->buffer == NULL)) {
		return -EINVAL;
	}

	if (src->bytesused < PERSON_DETECTION_MIPI_CAPTURE_FRAME_SIZE) {
		return -EINVAL;
	}

	memcpy(app_capture_mem + APP_CAPTURE_FULL_LATEST_FRAME_OFFSET,
	       src->buffer, PERSON_DETECTION_MIPI_CAPTURE_FRAME_SIZE);

	/* Match the parent usecase: crop the top-left 480x256 model window in place. */
	for (size_t row = 0U; row < 256U; row++) {
		memcpy(app_capture_mem + APP_CAPTURE_LATEST_FRAME_OFFSET +
		       (row * PERSON_DETECTION_MIPI_CAPTURE_WIDTH),
		       (const uint8_t *)src->buffer + (row * PERSON_DETECTION_MIPI_CAPTURE_PITCH),
		       PERSON_DETECTION_MIPI_CAPTURE_WIDTH);
	}
	ctx->latest_valid = true;
	ctx->latest_bytesused = PERSON_DETECTION_MIPI_MODEL_RAW_FRAME_SIZE;
	ctx->latest_timestamp = src->timestamp;
	ctx->latest_sequence++;
	ctx->frames_captured++;

	return 0;
}

static void capture_worker(void *arg1, void *arg2, void *arg3)
{
	struct capture_context *ctx = arg1;
	struct video_buffer *captured = NULL;
	bool started = false;
	int ret;

	ARG_UNUSED(arg2);
	ARG_UNUSED(arg3);

	ret = prepare_capture_buffers(ctx);
	if (ret != 0) {
		printk("person_detection_mipi: capture worker: prepare buffers failed: %d\n", ret);
		goto out;
	}

	ret = queue_capture_buffers(ctx);
	if (ret != 0) {
		printk("person_detection_mipi: capture worker: queue buffers failed: %d\n", ret);
		goto out;
	}

	ret = video_stream_start(ctx->mipi_dev, VIDEO_BUF_TYPE_OUTPUT);
	if (ret != 0) {
		printk("person_detection_mipi: capture worker: stream start failed: %d\n", ret);
		goto out;
	}
	started = true;

	while (!ctx->stop_requested) {
		ret = video_dequeue(ctx->mipi_dev, &captured, APP_CAPTURE_TIMEOUT);
		if (ret != 0) {
			if (ctx->stop_requested) {
				break;
			}
			printk("person_detection_mipi: capture worker: dequeue failed: %d\n", ret);
			goto out;
		}

		if (captured == NULL) {
			ret = -EIO;
			printk("person_detection_mipi: capture worker: dequeue returned NULL buffer\n");
			goto out;
		}

		k_mutex_lock(&ctx->lock, K_FOREVER);
		ret = copy_latest_frame_locked(ctx, captured);
		k_mutex_unlock(&ctx->lock);
		if (ret != 0) {
			printk("person_detection_mipi: capture worker: copy latest failed: %d\n", ret);
			goto out;
		}

		if ((ctx->latest_sequence <= 3U) || ((ctx->latest_sequence % 30U) == 0U)) {
			printk("person_detection_mipi: capture worker: frame seq=%u bytes=%u timestamp=%u total=%u\n",
			       ctx->latest_sequence, captured->bytesused, captured->timestamp,
			       ctx->frames_captured);
		}

		if (ctx->latest_sequence == 1U) {
			k_sem_give(&ctx->first_frame_sem);
		}

		ret = video_enqueue(ctx->mipi_dev, captured);
		captured = NULL;
		if (ret != 0) {
			printk("person_detection_mipi: capture worker: requeue failed: %d\n", ret);
			goto out;
		}

		ret = person_detection_mipi_stream_process_frame(
			app_capture_mem + APP_CAPTURE_FULL_LATEST_FRAME_OFFSET,
			PERSON_DETECTION_MIPI_CAPTURE_FRAME_SIZE, ctx->latest_sequence);
		if ((ret != 0) && (ret != -ENOTCONN) && (ret != -EAGAIN) &&
		    (ret != -ECANCELED)) {
			printk("person_detection_mipi: capture worker: stream process failed: %d\n",
			       ret);
		}
	}

out:
	if (captured != NULL) {
		(void)video_enqueue(ctx->mipi_dev, captured);
	}

	if (started) {
		(void)video_stream_stop(ctx->mipi_dev, VIDEO_BUF_TYPE_OUTPUT);
	}

	if (ctx->buffers_queued) {
		(void)video_flush(ctx->mipi_dev, true);
		drain_buffers(ctx->mipi_dev);
	}

	k_mutex_lock(&ctx->lock, K_FOREVER);
	ctx->worker_result = ret;
	ctx->stream_started = false;
	ctx->buffers_queued = false;
	ctx->state = CAPTURE_STATE_READY;
	k_mutex_unlock(&ctx->lock);

	k_sem_give(&ctx->worker_stopped_sem);
}

int person_detection_mipi_capture_init(void)
{
	struct capture_context *ctx = &app_ctx;
	int ret;

	capture_context_init(ctx);

	k_mutex_lock(&ctx->lock, K_FOREVER);

	if (ctx->state != CAPTURE_STATE_UNINITIALIZED) {
		k_mutex_unlock(&ctx->lock);
		return 0;
	}

	ret = prepare_device_locked(ctx);
	if (ret != 0) {
		printk("person_detection_mipi: video device preparation failed: %d\n", ret);
		k_mutex_unlock(&ctx->lock);
		return ret;
	}

	ret = configure_mipi_locked(ctx);
	if (ret != 0) {
		printk("person_detection_mipi: video format configuration failed: %d\n", ret);
		k_mutex_unlock(&ctx->lock);
		return ret;
	}

	ctx->state = CAPTURE_STATE_READY;

	k_mutex_unlock(&ctx->lock);
	return 0;
}

int person_detection_mipi_capture_start(void)
{
	struct capture_context *ctx = &app_ctx;
	int ret;

	capture_context_init(ctx);

	k_mutex_lock(&ctx->lock, K_FOREVER);
	if (ctx->state != CAPTURE_STATE_READY && ctx->state != CAPTURE_STATE_STOPPED) {
		k_mutex_unlock(&ctx->lock);
		return -EALREADY;
	}

	if (ctx->stream_started) {
		k_mutex_unlock(&ctx->lock);
		return 0;
	}

	/*
	 * Re-apply the MIPI configuration for every start cycle. The first cold
	 * boot start works reliably, but repeated start/stop cycles can leave the
	 * sensor/driver path needing an explicit refresh before streaming again.
	 */
	ret = prepare_device_locked(ctx);
	if (ret != 0) {
		k_mutex_unlock(&ctx->lock);
		printk("person_detection_mipi: start: video device preparation failed: %d\n", ret);
		return ret;
	}

	ret = configure_mipi_locked(ctx);
	if (ret != 0) {
		k_mutex_unlock(&ctx->lock);
		printk("person_detection_mipi: start: video format reconfiguration failed: %d\n",
		       ret);
		return ret;
	}

	ctx->stop_requested = false;
	ctx->frames_captured = 0U;
	ctx->latest_sequence = 0U;
	ctx->latest_valid = false;
	ctx->worker_result = 0;
	k_sem_reset(&ctx->first_frame_sem);
	k_sem_reset(&ctx->worker_stopped_sem);
	ctx->stream_started = true;
	k_mutex_unlock(&ctx->lock);

	k_thread_create(&ctx->worker_thread, capture_worker_stack,
			K_THREAD_STACK_SIZEOF(capture_worker_stack),
			capture_worker, ctx, NULL, NULL,
			CONFIG_HOST_API_TASK_PRIORITY, 0, K_NO_WAIT);
	k_thread_name_set(&ctx->worker_thread, "pd_mipi_capture");

	ret = k_sem_take(&ctx->first_frame_sem, APP_CAPTURE_FIRST_FRAME_TIMEOUT);
	if (ret != 0) {
		k_mutex_lock(&ctx->lock, K_FOREVER);
		ctx->stop_requested = true;
		k_mutex_unlock(&ctx->lock);
		(void)k_sem_take(&ctx->worker_stopped_sem, APP_CAPTURE_TIMEOUT);
		k_mutex_lock(&ctx->lock, K_FOREVER);
		ret = (ctx->worker_result != 0) ? ctx->worker_result : ret;
		k_mutex_unlock(&ctx->lock);
		return ret;
	}

	k_mutex_lock(&ctx->lock, K_FOREVER);
	ctx->state = CAPTURE_STATE_RUNNING;
	k_mutex_unlock(&ctx->lock);

	return 0;
}

int person_detection_mipi_capture_stop(void)
{
	struct capture_context *ctx = &app_ctx;
	int ret;

	capture_context_init(ctx);

	k_mutex_lock(&ctx->lock, K_FOREVER);
	if (!ctx->stream_started) {
		k_mutex_unlock(&ctx->lock);
		return 0;
	}

	ctx->stop_requested = true;
	k_mutex_unlock(&ctx->lock);

	ret = k_sem_take(&ctx->worker_stopped_sem, APP_CAPTURE_TIMEOUT);
	if (ret != 0) {
		return ret;
	}

	k_mutex_lock(&ctx->lock, K_FOREVER);
	ctx->state = CAPTURE_STATE_STOPPED;
	k_mutex_unlock(&ctx->lock);

	return 0;
}

int person_detection_mipi_capture_get_latest(struct person_detection_mipi_capture_frame *frame,
					     uint8_t *dst, size_t dst_size)
{
	struct capture_context *ctx = &app_ctx;
	int ret = 0;

	if ((frame == NULL) || (dst == NULL)) {
		return -EINVAL;
	}

	k_mutex_lock(&ctx->lock, K_FOREVER);
	if (!ctx->latest_valid) {
		ret = -EAGAIN;
		goto out;
	}

	if (dst_size < PERSON_DETECTION_MIPI_MODEL_RAW_FRAME_SIZE) {
		ret = -EINVAL;
		goto out;
	}

	memcpy(dst, app_capture_mem + APP_CAPTURE_LATEST_FRAME_OFFSET,
	       PERSON_DETECTION_MIPI_MODEL_RAW_FRAME_SIZE);
	frame->data = dst;
	frame->size = PERSON_DETECTION_MIPI_MODEL_RAW_FRAME_SIZE;
	frame->width = PERSON_DETECTION_MIPI_CAPTURE_WIDTH;
	frame->height = 256U;
	frame->pitch = PERSON_DETECTION_MIPI_CAPTURE_PITCH;
	frame->bytesused = ctx->latest_bytesused;
	frame->timestamp = ctx->latest_timestamp;
	frame->sequence = ctx->latest_sequence;
	frame->valid = true;

out:
	k_mutex_unlock(&ctx->lock);
	return ret;
}

int person_detection_mipi_capture_get_latest_full(struct person_detection_mipi_capture_frame *frame,
						  uint8_t *dst, size_t dst_size)
{
	struct capture_context *ctx = &app_ctx;
	int ret = 0;

	if ((frame == NULL) || (dst == NULL)) {
		return -EINVAL;
	}

	k_mutex_lock(&ctx->lock, K_FOREVER);
	if (!ctx->latest_valid) {
		ret = -EAGAIN;
		goto out;
	}

	if (dst_size < PERSON_DETECTION_MIPI_CAPTURE_FRAME_SIZE) {
		ret = -EINVAL;
		goto out;
	}

	memcpy(dst, app_capture_mem + APP_CAPTURE_FULL_LATEST_FRAME_OFFSET,
	       PERSON_DETECTION_MIPI_CAPTURE_FRAME_SIZE);
	frame->data = dst;
	frame->size = PERSON_DETECTION_MIPI_CAPTURE_FRAME_SIZE;
	frame->width = PERSON_DETECTION_MIPI_CAPTURE_WIDTH;
	frame->height = PERSON_DETECTION_MIPI_CAPTURE_HEIGHT;
	frame->pitch = PERSON_DETECTION_MIPI_CAPTURE_PITCH;
	frame->bytesused = PERSON_DETECTION_MIPI_CAPTURE_FRAME_SIZE;
	frame->timestamp = ctx->latest_timestamp;
	frame->sequence = ctx->latest_sequence;
	frame->valid = true;

out:
	k_mutex_unlock(&ctx->lock);
	return ret;
}

uint8_t *person_detection_mipi_capture_scratch_frame_buffer(void)
{
	return app_capture_mem + APP_CAPTURE_SCRATCH_FRAME_OFFSET;
}
```

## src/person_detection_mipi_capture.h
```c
/*
 * Copyright (c) 2026 Synaptics Incorporated
 *
 * SPDX-License-Identifier: Apache-2.0
 */

#ifndef PERSON_DETECTION_MIPI_CAPTURE_H_
#define PERSON_DETECTION_MIPI_CAPTURE_H_

#include <stddef.h>
#include <stdbool.h>
#include <stdint.h>

#ifdef __cplusplus
extern "C" {
#endif

#define PERSON_DETECTION_MIPI_CAPTURE_WIDTH 480U
#define PERSON_DETECTION_MIPI_CAPTURE_HEIGHT 270U
#define PERSON_DETECTION_MIPI_CAPTURE_PITCH PERSON_DETECTION_MIPI_CAPTURE_WIDTH
#define PERSON_DETECTION_MIPI_CAPTURE_FRAME_SIZE \
	((size_t)PERSON_DETECTION_MIPI_CAPTURE_WIDTH * \
	 (size_t)PERSON_DETECTION_MIPI_CAPTURE_HEIGHT)

/* OV02C10 provides 480x270 RAW8; the WQVGA model consumes its top 480x256 region. */
#define PERSON_DETECTION_MIPI_MODEL_RAW_FRAME_SIZE \
	((size_t)PERSON_DETECTION_MIPI_CAPTURE_WIDTH * 256U)

struct person_detection_mipi_capture_frame {
	const uint8_t *data;
	size_t size;
	uint32_t width;
	uint32_t height;
	uint32_t pitch;
	uint32_t bytesused;
	uint32_t timestamp;
	uint32_t sequence;
	bool valid;
};

int person_detection_mipi_capture_init(void);
int person_detection_mipi_capture_start(void);
int person_detection_mipi_capture_stop(void);
int person_detection_mipi_capture_get_latest(
	struct person_detection_mipi_capture_frame *frame,
	uint8_t *dst, size_t dst_size);
int person_detection_mipi_capture_get_latest_full(
	struct person_detection_mipi_capture_frame *frame,
	uint8_t *dst, size_t dst_size);
uint8_t *person_detection_mipi_capture_scratch_frame_buffer(void);

#ifdef __cplusplus
}
#endif

#endif /* PERSON_DETECTION_MIPI_CAPTURE_H_ */
```

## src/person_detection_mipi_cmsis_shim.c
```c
/*
 * Copyright (c) 2026 Synaptics Incorporated
 *
 * SPDX-License-Identifier: Apache-2.0
 */

#include <zephyr/kernel.h>
#include <stdint.h>

uint32_t osKernelGetTickCount(void)
{
	return k_uptime_ticks();
}

int32_t osDelay(uint32_t ticks)
{
	k_sleep(K_TICKS(ticks));
	return 0;
}
```

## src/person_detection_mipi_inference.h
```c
/*
 * Copyright (c) 2026 Synaptics Incorporated
 *
 * SPDX-License-Identifier: Apache-2.0
 */

#ifndef PERSON_DETECTION_MIPI_INFERENCE_H_
#define PERSON_DETECTION_MIPI_INFERENCE_H_

#include <stddef.h>
#include <stdint.h>

#include "infer_utils.h"

#ifdef __cplusplus
extern "C" {
#endif

#define PERSON_DETECTION_MIPI_INPUT_WIDTH 480
#define PERSON_DETECTION_MIPI_INPUT_HEIGHT 256
#define PERSON_DETECTION_MIPI_INPUT_CHANNELS 3
#define PERSON_DETECTION_MIPI_INPUT_SIZE \
	(PERSON_DETECTION_MIPI_INPUT_WIDTH * PERSON_DETECTION_MIPI_INPUT_HEIGHT * \
	 PERSON_DETECTION_MIPI_INPUT_CHANNELS)

struct person_detection_mipi_inference_result {
	uint32_t invoke_time_ms;
	int detection_count;
	detection_t detections[MAX_DETECTIONS];
};

int person_detection_mipi_inference_init(void);
int person_detection_mipi_inference_run_rgb_frame(
	const uint8_t *rgb_frame, size_t rgb_frame_size,
	struct person_detection_mipi_inference_result *result);
int person_detection_mipi_inference_run_raw8_frame(
	const uint8_t *raw_frame, size_t raw_frame_size,
	struct person_detection_mipi_inference_result *result);

#ifdef __cplusplus
}
#endif

#endif /* PERSON_DETECTION_MIPI_INFERENCE_H_ */
```

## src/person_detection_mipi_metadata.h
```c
/*
 * Copyright (c) 2026 Synaptics Incorporated
 *
 * SPDX-License-Identifier: Apache-2.0
 */

#ifndef PERSON_DETECTION_MIPI_METADATA_H_
#define PERSON_DETECTION_MIPI_METADATA_H_

#include <stddef.h>
#include <stdint.h>
#include <stdbool.h>

#include "person_detection_mipi_inference.h"

#ifdef __cplusplus
extern "C" {
#endif

int person_detection_mipi_metadata_update(
	uint32_t frame_sequence, uint8_t usecase_id,
	const struct person_detection_mipi_inference_result *result);
int person_detection_mipi_metadata_get(char *dst, size_t dst_size);

struct person_detection_mipi_metadata_snapshot {
	uint32_t frame_sequence;
	uint32_t invoke_time_ms;
	int detection_count;
	detection_t detections[MAX_DETECTIONS];
	uint8_t usecase_id;
	bool valid;
};

int person_detection_mipi_metadata_snapshot_get(
	struct person_detection_mipi_metadata_snapshot *snapshot);
void person_detection_mipi_metadata_reset(void);

#ifdef __cplusplus
}
#endif

#endif /* PERSON_DETECTION_MIPI_METADATA_H_ */
```
